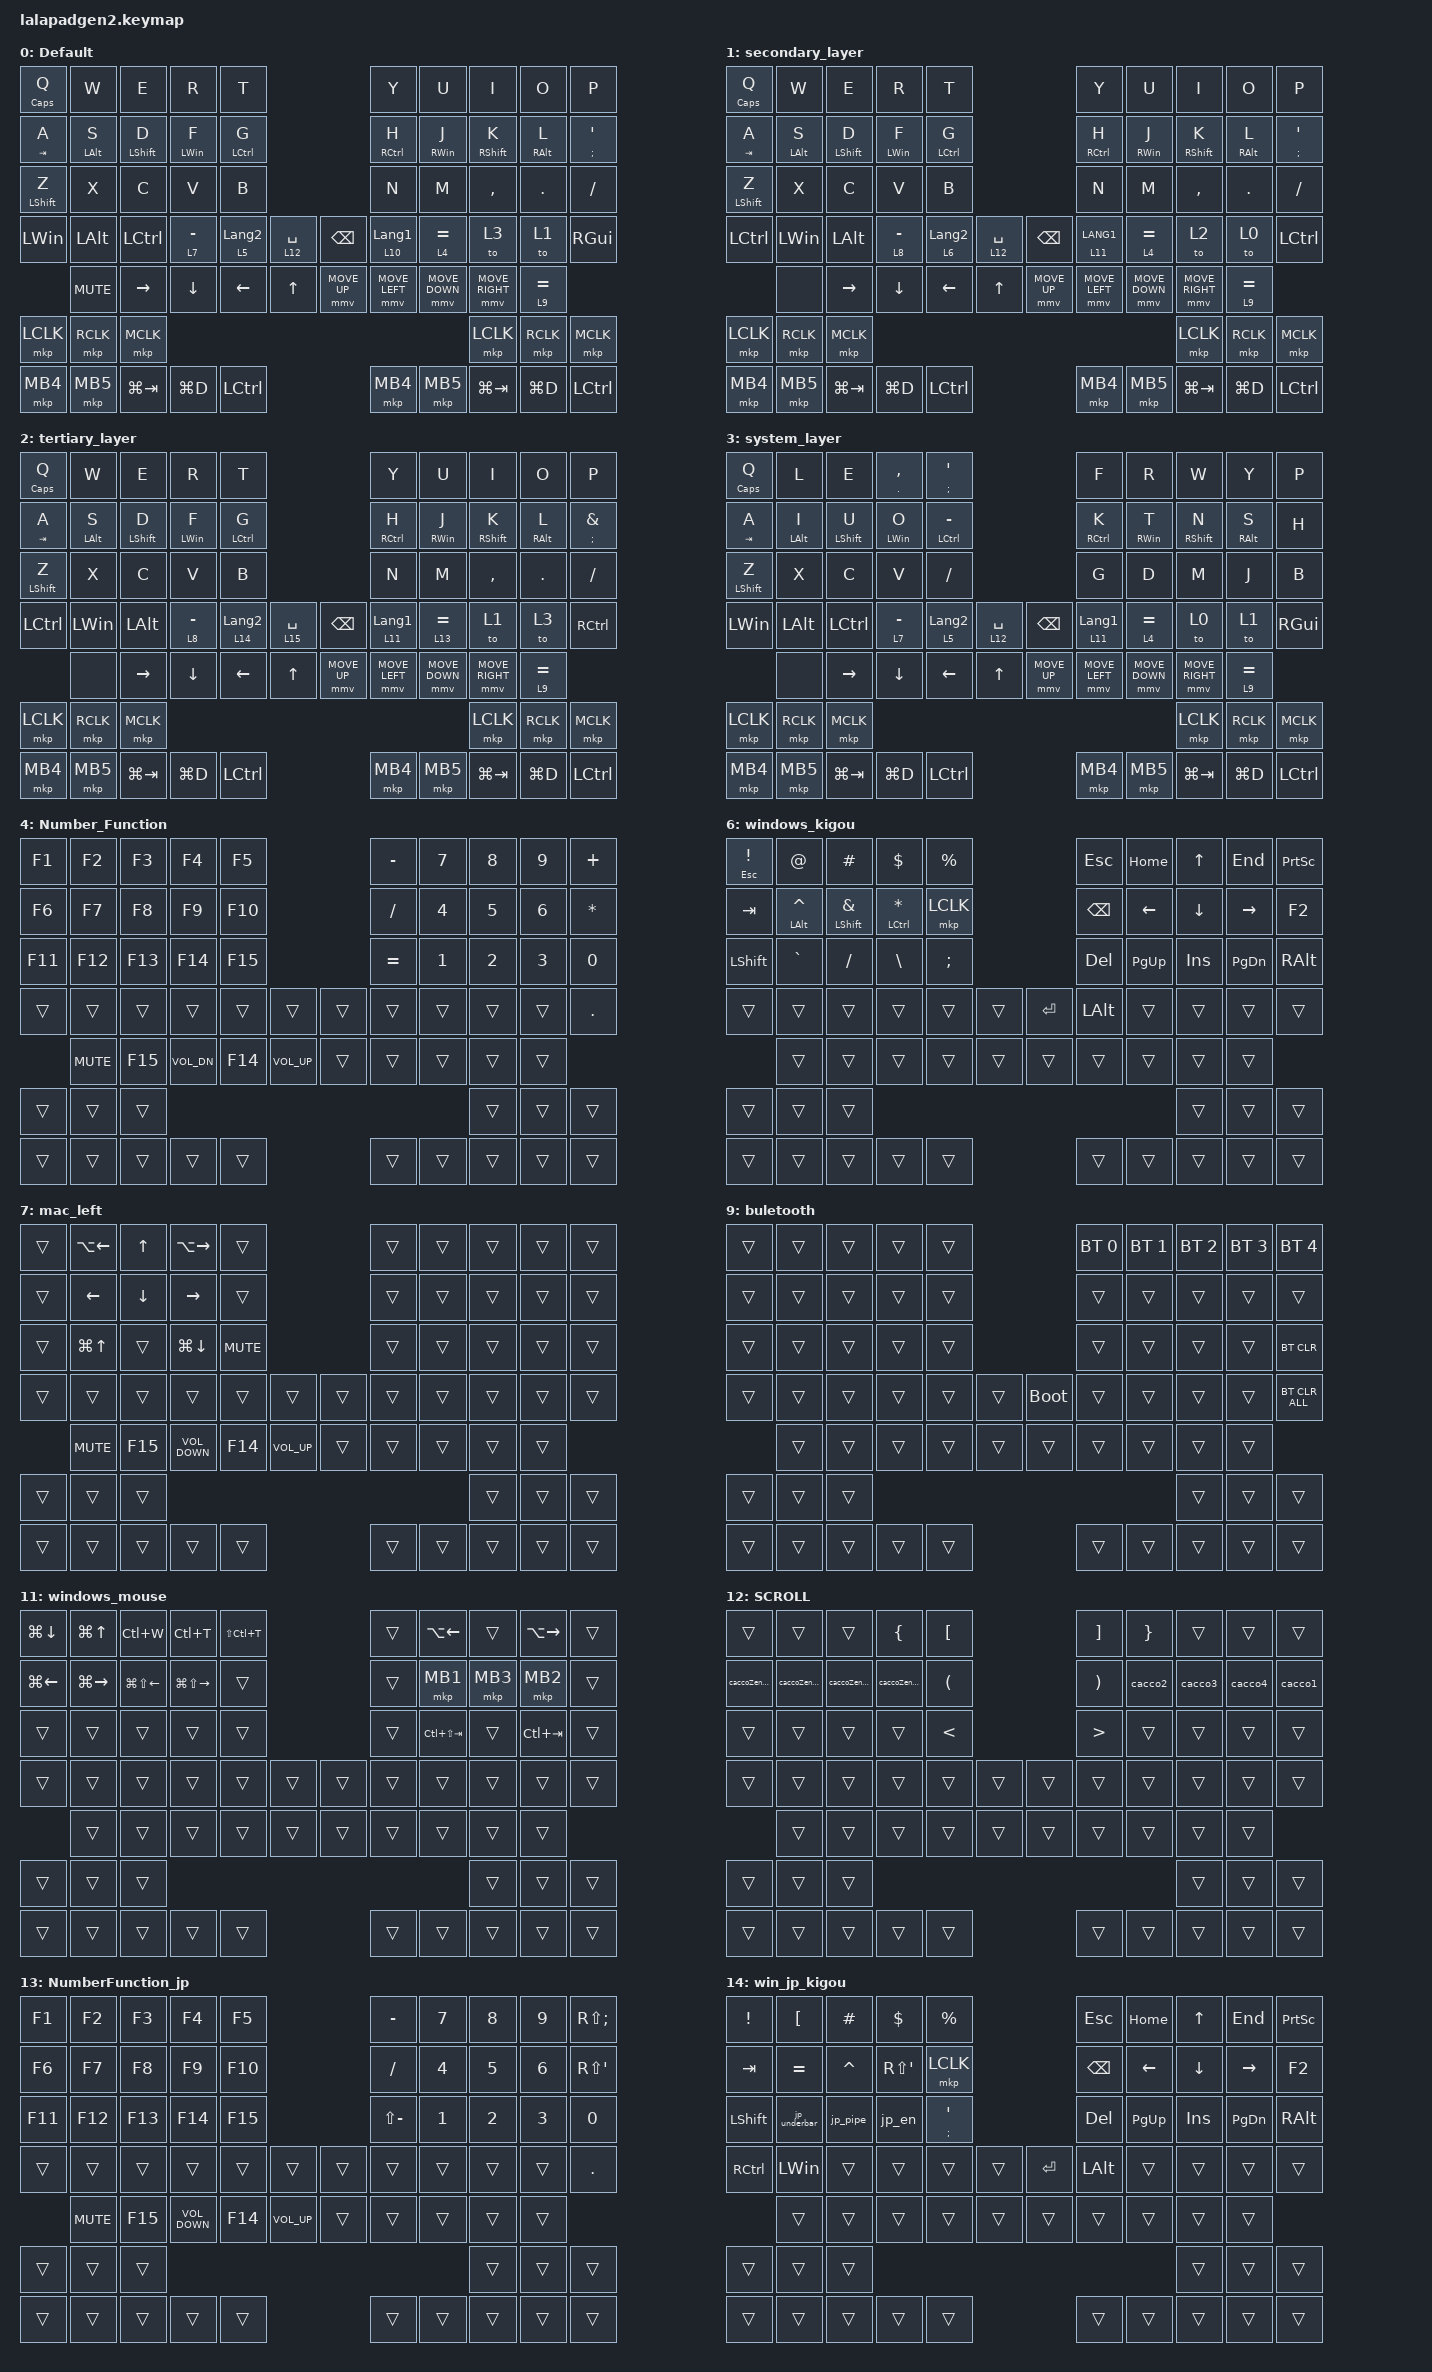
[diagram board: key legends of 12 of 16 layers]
#include <input/processors.dtsi>
#include <dt-bindings/zmk/zip_dynamic_scale.h>
#include <behaviors.dtsi>
#include <dt-bindings/zmk/bt.h>
#include <dt-bindings/zmk/keys.h>
#include <dt-bindings/zmk/pointing.h>

#define DEFAULT_LAYER   0
#define SECONDARY_LAYER 1
#define TERTIARY_LAYER  2
#define SYSTEM_LAYER    3

// &mt { quick-tap-ms = <200>; };

&mt {
    quick-tap-ms = <0>;
    flavor = "balanced";
};

// &lt { quick-tap-ms = <200>; };

&lt {
    quick-tap-ms = <300>;
    flavor = "balanced";
};

/ {
    behaviors {
        zip_dyn_scale: zip_dyn_scale {
            compatible = "zmk,behavior-zip-dynamic-scale";
            #binding-cells = <2>;
        };

        zip_dyn_scale_set: zip_dyn_scale_set {
            compatible = "zmk,behavior-zip-dynamic-scale-set";
            #binding-cells = <2>;
        };

        mt2: mod_tap2 {
            compatible = "zmk,behavior-hold-tap";
            #binding-cells = <2>;
            flavor = "tap-preferred";
            tapping-term-ms = <200>;
            quick-tap-ms = <200>;
            require-prior-idle-ms = <125>;
            bindings = <&kp>, <&kp>;
        };

        tap_dance_layer_1and2: tap_dance_layer_1and2 {
            compatible = "zmk,behavior-tap-dance";
            label = "td_mo12";
            #binding-cells = <0>;
            bindings = <&mo 1>, <&mo 2>;
        };
    };

    combos {
        compatible = "zmk,combos";

        CONBO_ESC {
            bindings = <&kp ESCAPE>;
            key-positions = <0 1>;
            layers = <12>;
        };

        COMBO_TAB {
            bindings = <&kp TAB>;
            key-positions = <10 11>;
            layers = <12>;
        };
    };

    macros {
        to_layer_0: to_layer_0 {
            compatible = "zmk,behavior-macro-one-param";
            #binding-cells = <1>;
            bindings = <&to 1 &macro_param_1to1 &kp MACRO_PLACEHOLDER>;
            label = "TO_LAYER_0";
        };

        cacco1: cacco1 {
            compatible = "zmk,behavior-macro";
            #binding-cells = <0>;
            bindings = <&kp LANGUAGE_1 &kp LEFT_BRACE &kp RIGHT_BRACE &kp RET &kp LEFT_ARROW>;
            label = "CACCO1";
        };

        cacco2: cacco2 {
            compatible = "zmk,behavior-macro";
            #binding-cells = <0>;
            bindings = <&kp LANGUAGE_1 &kp LEFT_PARENTHESIS &kp RIGHT_PARENTHESIS &kp RETURN &kp LEFT>;
            label = "CACCO2";
        };

        cacco3: cacco3 {
            compatible = "zmk,behavior-macro";
            #binding-cells = <0>;
            bindings = <&kp LANGUAGE_1 &kp LEFT_BRACKET &kp RIGHT_BRACKET &kp RET &kp LEFT>;
            label = "CACCO3";
        };

        cacco4: cacco4 {
            compatible = "zmk,behavior-macro";
            #binding-cells = <0>;
            bindings = <&kp LANGUAGE_1 &kp LESS_THAN &kp GREATER_THAN &kp RET &kp LEFT_ARROW>;
            label = "CACCO4";
        };

        caccoZenkaku1: caccoZenkaku1 {
            compatible = "zmk,behavior-macro";
            #binding-cells = <0>;
            bindings = <&kp LANGUAGE_2 &kp LEFT_BRACE &kp RIGHT_BRACE &kp LEFT>;
            label = "CACCOZENKAKU1";
        };

        caccoZenkaku2: caccoZenkaku2 {
            compatible = "zmk,behavior-macro";
            #binding-cells = <0>;
            bindings = <&kp LANGUAGE_2 &kp LEFT_PARENTHESIS &kp RIGHT_PARENTHESIS &kp LEFT_ARROW>;
            label = "CACCOZENKAKU2";
        };

        caccoZenkaku3: caccoZenkaku3 {
            compatible = "zmk,behavior-macro";
            #binding-cells = <0>;
            bindings = <&kp LANGUAGE_2 &kp LEFT_BRACKET &kp RIGHT_BRACKET &kp LEFT>;
            label = "CACCOZENKAKU3";
        };

        caccoZenkaku4: caccoZenkaku4 {
            compatible = "zmk,behavior-macro";
            #binding-cells = <0>;
            bindings = <&kp LANGUAGE_2 &kp LESS_THAN &kp GREATER_THAN &kp LEFT>;
            label = "CACCOZENKAKU4";
        };

        cacco1JpHankaku: cacco1JpHankaku {
            compatible = "zmk,behavior-macro";
            #binding-cells = <0>;
            bindings = <&kp LANGUAGE_2 &kp RIGHT_BRACE &kp LS(BACKSLASH) &kp LEFT_ARROW>;
            label = "CACCO1JPHANKAKU";
        };

        cacco2JpHankaku: cacco2JpHankaku {
            compatible = "zmk,behavior-macro";
            #binding-cells = <0>;
            bindings = <&kp LANGUAGE_2 &kp ASTERISK &kp LEFT_PARENTHESIS &kp LEFT>;
            label = "CACCO2JPHANKAKU";
        };

        cacco3JpHankaku: cacco3JpHankaku {
            compatible = "zmk,behavior-macro";
            #binding-cells = <0>;
            bindings = <&kp LANGUAGE_2 &kp RIGHT_BRACKET &kp BACKSLASH &kp LEFT>;
            label = "CACCO3JPHANKAKU";
        };

        cacco4JpHankaku: cacco4JpHankaku {
            compatible = "zmk,behavior-macro";
            #binding-cells = <0>;
            bindings = <&kp LANGUAGE_2 &kp LESS_THAN &kp GREATER_THAN &kp LEFT>;
            label = "CACCO4JPHANKAKU";
        };

        cacco1JpZenkaku: cacco1JpZenkaku {
            compatible = "zmk,behavior-macro";
            #binding-cells = <0>;
            bindings = <&kp LANGUAGE_1 &kp RIGHT_BRACE &kp LS(BACKSLASH) &kp ENTER &kp LEFT>;
            label = "CACCO1JPZENKAKU";
        };

        cacco2JpZenkaku: cacco2JpZenkaku {
            compatible = "zmk,behavior-macro";
            #binding-cells = <0>;
            bindings = <&kp LANGUAGE_1 &kp ASTERISK &kp LEFT_PARENTHESIS &kp ENTER &kp LEFT_ARROW>;
            label = "CACCO2JPZENKAKU";
        };

        cacco3JpZenkaku: cacco3JpZenkaku {
            compatible = "zmk,behavior-macro";
            #binding-cells = <0>;
            bindings = <&kp LANGUAGE_1 &kp RIGHT_BRACKET &kp BACKSLASH &kp ENTER &kp LEFT>;
            label = "CACCO3JPZENKAKU";
        };

        cacco4JpZenkaku: cacco4JpZenkaku {
            compatible = "zmk,behavior-macro";
            #binding-cells = <0>;
            bindings = <&kp LANGUAGE_1 &kp LESS_THAN &kp GREATER_THAN &kp ENTER &kp LEFT>;
            label = "CACCO4JPZENKAKU";
        };

        jp_underbar: jp_underbar {
            compatible = "zmk,behavior-macro";
            #binding-cells = <0>;
            bindings =
                <&kp LANGUAGE_1 &kp L &kp A &kp I>,
                <&macro_wait_time 1>,
                <&kp TAB>,
                <&macro_wait_time 1>,
                <&kp ENTER &kp LANGUAGE_2>;

            label = "JP_UNDERBAR";
            wait-ms = <5>;
        };

        jp_pipe: jp_pipe {
            compatible = "zmk,behavior-macro";
            #binding-cells = <0>;
            bindings =
                <&kp LANGUAGE_1 &kp L &kp U &kp A>,
                <&macro_wait_time 1>,
                <&kp TAB>,
                <&macro_wait_time 1>,
                <&kp ENTER &kp LANGUAGE_2>;

            label = "JP_PIPE";
            wait-ms = <5>;
        };

        jp_en: jp_en {
            compatible = "zmk,behavior-macro";
            #binding-cells = <0>;
            bindings =
                <&kp LANG_HANGEUL &kp L &kp E &kp A>,
                <&macro_wait_time 1>,
                <&kp TAB>,
                <&macro_wait_time 1>,
                <&kp ENTER &kp LANGUAGE_2>;

            label = "JP_EN";
            wait-ms = <5>;
        };
    };

    keymap {
        compatible = "zmk,keymap";

        mac_default {
            display-name = "Default";
            bindings = <
&mt CAPS Q         &kp W           &kp E         &kp R           &kp T                                          &kp Y              &kp U            &kp I            &kp O            &kp P
&mt TAB A          &mt LEFT_ALT S  &mt LSHIFT D  &mt LEFT_WIN F  &mt LCTRL G                                    &mt RCTRL H        &mt RIGHT_WIN J  &mt RSHIFT K     &mt RIGHT_ALT L  &mt SEMICOLON SINGLE_QUOTE
&mt2 LEFT_SHIFT Z  &kp X           &kp C         &kp V           &kp B                                          &kp N              &kp M            &kp COMMA        &kp PERIOD       &kp SLASH
&kp LEFT_WIN       &kp LEFT_ALT    &kp LCTRL     &lt 7 MINUS     &lt 5 LANGUAGE_2  &lt 12 SPACE  &kp BACKSPACE  &lt 10 LANGUAGE_1  &lt 4 EQUAL      &to 3            &to 1            &kp RIGHT_GUI
                   &kp C_MUTE      &kp RIGHT     &kp DOWN        &kp LEFT          &kp UP        &mmv MOVE_UP   &mmv MOVE_LEFT     &mmv MOVE_DOWN   &mmv MOVE_RIGHT  &lt 9 EQUAL
&mkp LCLK          &mkp RCLK       &mkp MCLK                                                                                                        &mkp LCLK        &mkp RCLK        &mkp MCLK
&mkp MB4           &mkp MB5        &kp LG(TAB)   &kp LG(D)       &kp LCTRL                                      &mkp MB4           &mkp MB5         &kp LG(TAB)      &kp LG(D)        &kp LCTRL
            >;
        };

        windows_default {
            display-name = "secondary_layer";
            bindings = <
&mt CAPS Q         &kp W           &kp E         &kp R           &kp T                                          &kp Y           &kp U            &kp I            &kp O            &kp P
&mt TAB A          &mt LEFT_ALT S  &mt LSHIFT D  &mt LEFT_WIN F  &mt LCTRL G                                    &mt RCTRL H     &mt RIGHT_WIN J  &mt RSHIFT K     &mt RIGHT_ALT L  &mt SEMICOLON SINGLE_QUOTE
&mt2 LEFT_SHIFT Z  &kp X           &kp C         &kp V           &kp B                                          &kp N           &kp M            &kp COMMA        &kp PERIOD       &kp SLASH
&kp LCTRL          &kp LEFT_WIN    &kp LEFT_ALT  &lt 8 MINUS     &lt 6 LANGUAGE_2  &lt 12 SPACE  &kp BACKSPACE  &lt 11 LANG1    &lt 4 EQUAL      &to 2            &to 0            &kp LCTRL
                   &none           &kp RIGHT     &kp DOWN        &kp LEFT          &kp UP        &mmv MOVE_UP   &mmv MOVE_LEFT  &mmv MOVE_DOWN   &mmv MOVE_RIGHT  &lt 9 EQUAL
&mkp LCLK          &mkp RCLK       &mkp MCLK                                                                                                     &mkp LCLK        &mkp RCLK        &mkp MCLK
&mkp MB4           &mkp MB5        &kp LG(TAB)   &kp LG(D)       &kp LCTRL                                      &mkp MB4        &mkp MB5         &kp LG(TAB)      &kp LG(D)        &kp LCTRL
            >;
        };

        windows_jp {
            display-name = "tertiary_layer";
            bindings = <
&mt CAPS Q         &kp W           &kp E         &kp R           &kp T                                           &kp Y              &kp U            &kp I            &kp O            &kp P
&mt TAB A          &mt LEFT_ALT S  &mt LSHIFT D  &mt LEFT_WIN F  &mt LCTRL G                                     &mt RCTRL H        &mt RIGHT_WIN J  &mt RSHIFT K     &mt RIGHT_ALT L  &mt SEMICOLON AMPERSAND
&mt2 LEFT_SHIFT Z  &kp X           &kp C         &kp V           &kp B                                           &kp N              &kp M            &kp COMMA        &kp PERIOD       &kp SLASH
&kp LCTRL          &kp LEFT_WIN    &kp LEFT_ALT  &lt 8 MINUS     &lt 14 LANGUAGE_2  &lt 15 SPACE  &kp BACKSPACE  &lt 11 LANGUAGE_1  &lt 13 EQUAL     &to 1            &to 3            &kp RCTRL
                   &none           &kp RIGHT     &kp DOWN        &kp LEFT           &kp UP        &mmv MOVE_UP   &mmv MOVE_LEFT     &mmv MOVE_DOWN   &mmv MOVE_RIGHT  &lt 9 EQUAL
&mkp LCLK          &mkp RCLK       &mkp MCLK                                                                                                         &mkp LCLK        &mkp RCLK        &mkp MCLK
&mkp MB4           &mkp MB5        &kp LG(TAB)   &kp LG(D)       &kp LCTRL                                       &mkp MB4           &mkp MB5         &kp LG(TAB)      &kp LG(D)        &kp LCTRL
            >;
        };

        mac_onisi {
            display-name = "system_layer";
            bindings = <
&mt CAPS Q         &kp L           &kp E         &mt PERIOD COMMA  &mt SEMICOLON SQT                               &kp F              &kp R            &kp W            &kp Y            &kp P
&mt TAB A          &mt LEFT_ALT I  &mt LSHIFT U  &mt LEFT_WIN O    &mt LCTRL MINUS                                 &mt RCTRL K        &mt RIGHT_WIN T  &mt RSHIFT N     &mt RIGHT_ALT S  &kp H
&mt2 LEFT_SHIFT Z  &kp X           &kp C         &kp V             &kp SLASH                                       &kp G              &kp D            &kp M            &kp J            &kp B
&kp LEFT_WIN       &kp LEFT_ALT    &kp LCTRL     &lt 7 MINUS       &lt 5 LANGUAGE_2   &lt 12 SPACE  &kp BACKSPACE  &lt 11 LANGUAGE_1  &lt 4 EQUAL      &to 0            &to 1            &kp RIGHT_GUI
                   &none           &kp RIGHT     &kp DOWN          &kp LEFT           &kp UP        &mmv MOVE_UP   &mmv MOVE_LEFT     &mmv MOVE_DOWN   &mmv MOVE_RIGHT  &lt 9 EQUAL
&mkp LCLK          &mkp RCLK       &mkp MCLK                                                                                                           &mkp LCLK        &mkp RCLK        &mkp MCLK
&mkp MB4           &mkp MB5        &kp LG(TAB)   &kp LG(D)         &kp LCTRL                                       &mkp MB4           &mkp MB5         &kp LG(TAB)      &kp LG(D)        &kp LCTRL
            >;
        };

        Number_Function {
            bindings = <
&kp F1   &kp F2      &kp F3   &kp F4        &kp F5                            &kp MINUS  &kp N7  &kp N8  &kp N9  &kp PLUS
&kp F6   &kp F7      &kp F8   &kp F9        &kp F10                           &kp SLASH  &kp N4  &kp N5  &kp N6  &kp ASTERISK
&kp F11  &kp F12     &kp F13  &kp F14       &kp F15                           &kp EQUAL  &kp N1  &kp N2  &kp N3  &kp N0
&trans   &trans      &trans   &trans        &trans   &trans           &trans  &trans     &trans  &trans  &trans  &kp DOT
         &kp C_MUTE  &kp F15  &kp C_VOL_DN  &kp F14  &kp C_VOLUME_UP  &trans  &trans     &trans  &trans  &trans
&trans   &trans      &trans                                                                      &trans  &trans  &trans
&trans   &trans      &trans   &trans        &trans                            &trans     &trans  &trans  &trans  &trans
            >;
        };

        mac_kigou {
            bindings = <
&mt ESCAPE EXCLAMATION  &kp AT_SIGN         &kp HASH                  &kp DOLLAR          &kp PERCENT                       &kp ESCAPE     &kp LG(LEFT)      &kp UP_ARROW  &kp LG(RIGHT)  &kp LC(LS(LG(NUMBER_4)))
&kp TAB                 &mt LEFT_ALT CARET  &mt LEFT_SHIFT AMPERSAND  &mt LCTRL ASTERISK  &mkp LCLK                         &kp BACKSPACE  &kp LEFT_ARROW    &kp DOWN      &kp RIGHT      &kp LC(U)
&kp LSHIFT              &kp GRAVE           &kp SLASH                 &kp BACKSLASH       &kp SEMICOLON                     &kp DELETE     &kp LG(UP_ARROW)  &kp INS       &kp LG(DOWN)   &kp RIGHT_ALT
&trans                  &trans              &trans                    &trans              &trans         &trans  &kp ENTER  &kp LEFT_ALT   &trans            &trans        &trans         &kp LS(LG(NUMBER_3))
                        &kp C_MUTE          &trans                    &trans              &trans         &trans  &trans     &trans         &trans            &trans        &trans
&trans                  &trans              &trans                                                                                                           &trans        &trans         &trans
&trans                  &trans              &trans                    &trans              &trans                            &trans         &trans            &trans        &trans         &trans
            >;
        };

        windows_kigou {
            bindings = <
&mt ESCAPE EXCLAMATION  &kp AT_SIGN         &kp HASH                  &kp DOLLAR          &kp PERCENT                       &kp ESCAPE     &kp HOME        &kp UP_ARROW  &kp END        &kp PRINTSCREEN
&kp TAB                 &mt LEFT_ALT CARET  &mt LEFT_SHIFT AMPERSAND  &mt LCTRL ASTERISK  &mkp LCLK                         &kp BACKSPACE  &kp LEFT_ARROW  &kp DOWN      &kp RIGHT      &kp F2
&kp LSHIFT              &kp GRAVE           &kp SLASH                 &kp BACKSLASH       &kp SEMICOLON                     &kp DELETE     &kp PAGE_UP     &kp INS       &kp PAGE_DOWN  &kp RIGHT_ALT
&trans                  &trans              &trans                    &trans              &trans         &trans  &kp ENTER  &kp LEFT_ALT   &trans          &trans        &trans         &trans
                        &trans              &trans                    &trans              &trans         &trans  &trans     &trans         &trans          &trans        &trans
&trans                  &trans              &trans                                                                                                         &trans        &trans         &trans
&trans                  &trans              &trans                    &trans              &trans                            &trans         &trans          &trans        &trans         &trans
            >;
        };

        mac_left {
            bindings = <
&trans  &kp LA(LEFT_ARROW)  &kp UP_ARROW  &kp LA(RIGHT)      &trans                               &trans  &trans  &trans  &trans  &trans
&trans  &kp LEFT_ARROW      &kp DOWN      &kp RIGHT          &trans                               &trans  &trans  &trans  &trans  &trans
&trans  &kp LG(UP_ARROW)    &trans        &kp LG(DOWN)       &kp C_MUTE                           &trans  &trans  &trans  &trans  &trans
&trans  &trans              &trans        &trans             &trans      &trans           &trans  &trans  &trans  &trans  &trans  &trans
        &kp C_MUTE          &kp F15       &kp C_VOLUME_DOWN  &kp F14     &kp C_VOLUME_UP  &trans  &trans  &trans  &trans  &trans
&trans  &trans              &trans                                                                                &trans  &trans  &trans
&trans  &trans              &trans        &trans             &trans                               &trans  &trans  &trans  &trans  &trans
            >;
        };

        win_left {
            bindings = <
&kp ESCAPE      &kp LC(LS(TAB))   &kp UP_ARROW    &kp LC(TAB)        &trans                   &trans  &trans  &trans  &trans  &trans
&kp HOME        &kp LEFT_ARROW    &kp DOWN_ARROW  &kp RIGHT_ARROW    &kp END                  &trans  &trans  &trans  &trans  &trans
&kp LEFT_SHIFT  &kp LG(LS(LEFT))  &trans          &kp LG(LS(RIGHT))  &trans                   &trans  &trans  &trans  &trans  &trans
&trans          &trans            &trans          &trans             &trans   &trans  &trans  &trans  &trans  &trans  &trans  &trans
                &trans            &trans          &trans             &trans   &trans  &trans  &trans  &trans  &trans  &trans
&trans          &trans            &trans                                                                      &trans  &trans  &trans
&trans          &trans            &trans          &trans             &trans                   &trans  &trans  &trans  &trans
            >;
        };

        buletooth {
            bindings = <
&trans  &trans  &trans  &trans  &trans                       &bt BT_SEL 0  &bt BT_SEL 1  &bt BT_SEL 2  &bt BT_SEL 3  &bt BT_SEL 4
&trans  &trans  &trans  &trans  &trans                       &trans        &trans        &trans        &trans        &trans
&trans  &trans  &trans  &trans  &trans                       &trans        &trans        &trans        &trans        &bt BT_CLR
&trans  &trans  &trans  &trans  &trans  &trans  &bootloader  &trans        &trans        &trans        &trans        &bt BT_CLR_ALL
        &trans  &trans  &trans  &trans  &trans  &trans       &trans        &trans        &trans        &trans
&trans  &trans  &trans                                                                   &trans        &trans        &trans
&trans  &trans  &trans  &trans  &trans                       &trans        &trans        &trans        &trans        &trans
            >;
        };

        mac_mouse {
            bindings = <
&kp LG(LC(LA(N)))  &kp LG(LA(LC(LEFT_ARROW)))  &kp LG(LC(UP_ARROW))    &kp LG(LA(LC(UP_ARROW)))  &kp LG(BACKSLASH)                  &trans  &kp LG(LEFT_BRACKET)  &trans     &kp LG(RIGHT_BRACKET)  &trans
&kp LC(UP)         &kp LG(LC(LEFT))            &kp LG(LC(DOWN_ARROW))  &kp LG(LC(RIGHT))         &kp LG(LS(LC(D)))                  &trans  &mkp LCLK             &mkp MCLK  &mkp RCLK              &trans
&kp LC(DOWN)       &kp LG(LC(LA(DOWN_ARROW)))  &trans                  &kp LC(LA(LG(RIGHT)))     &trans                             &trans  &kp LC(LS(TAB))       &trans     &kp LC(TAB)            &trans
&trans             &trans                      &trans                  &trans                    &trans             &trans  &trans  &trans  &trans                &trans     &trans                 &trans
                   &trans                      &trans                  &trans                    &trans             &trans  &trans  &trans  &trans                &trans     &trans
&trans             &trans                      &trans                                                                                                             &trans     &trans                 &trans
&trans             &trans                      &trans                  &trans                    &trans                             &trans  &trans                &trans     &trans                 &trans
            >;
        };

        windows_mouse {
            bindings = <
&kp LG(DOWN)  &kp LG(UP_ARROW)  &kp LC(W)         &kp LC(T)          &kp LS(LC(T))                  &trans  &kp LA(LEFT)     &trans    &kp LA(RIGHT)  &trans
&kp LG(LEFT)  &kp LG(RIGHT)     &kp LG(LS(LEFT))  &kp LG(LS(RIGHT))  &trans                         &trans  &mkp MB1         &mkp MB3  &mkp MB2       &trans
&trans        &trans            &trans            &trans             &trans                         &trans  &kp LC(LS(TAB))  &trans    &kp LC(TAB)    &trans
&trans        &trans            &trans            &trans             &trans         &trans  &trans  &trans  &trans           &trans    &trans         &trans
              &trans            &trans            &trans             &trans         &trans  &trans  &trans  &trans           &trans    &trans
&trans        &trans            &trans                                                                                       &trans    &trans         &trans
&trans        &trans            &trans            &trans             &trans                         &trans  &trans           &trans    &trans         &trans
            >;
        };

        SCROLL {
            bindings = <
&trans          &trans          &trans          &kp LEFT_BRACE  &kp LEFT_BRACKET                      &kp RIGHT_BRACKET      &kp RIGHT_BRACE  &trans   &trans   &trans
&caccoZenkaku1  &caccoZenkaku4  &caccoZenkaku3  &caccoZenkaku2  &kp LEFT_PARENTHESIS                  &kp RIGHT_PARENTHESIS  &cacco2          &cacco3  &cacco4  &cacco1
&trans          &trans          &trans          &trans          &kp LESS_THAN                         &kp GREATER_THAN       &trans           &trans   &trans   &trans
&trans          &trans          &trans          &trans          &trans                &trans  &trans  &trans                 &trans           &trans   &trans   &trans
                &trans          &trans          &trans          &trans                &trans  &trans  &trans                 &trans           &trans   &trans
&trans          &trans          &trans                                                                                                        &trans   &trans   &trans
&trans          &trans          &trans          &trans          &trans                                &trans                 &trans           &trans   &trans   &trans
            >;
        };

        NumberFunction_jp {
            bindings = <
&kp F1   &kp F2      &kp F3   &kp F4             &kp F5                            &kp MINUS      &kp N7        &kp N8        &kp N9        &kp RS(SEMICOLON)
&kp F6   &kp F7      &kp F8   &kp F9             &kp F10                           &kp SLASH      &kp NUMBER_4  &kp N5        &kp NUMBER_6  &kp RS(SINGLE_QUOTE)
&kp F11  &kp F12     &kp F13  &kp F14            &kp F15                           &kp LS(MINUS)  &kp NUMBER_1  &kp NUMBER_2  &kp NUMBER_3  &kp N0
&trans   &trans      &trans   &trans             &trans   &trans           &trans  &trans         &trans        &trans        &trans        &kp PERIOD
         &kp C_MUTE  &kp F15  &kp C_VOLUME_DOWN  &kp F14  &kp C_VOLUME_UP  &trans  &trans         &trans        &trans        &trans
&trans   &trans      &trans                                                                                     &trans        &trans        &trans
&trans   &trans      &trans   &trans             &trans                            &trans         &trans        &trans        &trans        &trans
            >;
        };

        win_jp_kigou {
            bindings = <
&kp EXCLAMATION  &kp LEFT_BRACKET  &kp HASH   &kp DOLLAR            &kp PERCENT                                    &kp ESC        &kp HOME     &kp UP_ARROW    &kp END        &kp PRINTSCREEN
&kp TAB          &kp EQUAL         &kp CARET  &kp RS(SINGLE_QUOTE)  &mkp LCLK                                      &kp BACKSPACE  &kp LEFT     &kp DOWN_ARROW  &kp RIGHT      &kp F2
&kp LSHIFT       &jp_underbar      &jp_pipe   &jp_en                &mt SEMICOLON SINGLE_QUOTE                     &kp DELETE     &kp PAGE_UP  &kp INS         &kp PAGE_DOWN  &kp RIGHT_ALT
&kp RCTRL        &kp LEFT_WIN      &trans     &trans                &trans                      &trans  &kp ENTER  &kp LEFT_ALT   &trans       &trans          &trans         &trans
                 &trans            &trans     &trans                &trans                      &trans  &trans     &trans         &trans       &trans          &trans
&trans           &trans            &trans                                                                                                      &trans          &trans         &trans
&trans           &trans            &trans     &trans                &trans                                         &trans         &trans       &trans          &trans         &trans
            >;
        };

        windows_jp_kakko {
            bindings = <
&trans            &trans            &trans            &kp RBRC          &kp RIGHT_BRACKET                  &kp BACKSLASH         &kp LS(BACKSLASH)  &trans            &trans            &trans
&cacco1JpHankaku  &cacco4JpHankaku  &cacco3JpHankaku  &cacco2JpHankaku  &kp ASTERISK                       &kp LEFT_PARENTHESIS  &cacco2JpZenkaku   &cacco3JpZenkaku  &cacco4JpZenkaku  &cacco1JpZenkaku
&trans            &trans            &trans            &trans            &kp LESS_THAN                      &kp GREATER_THAN      &trans             &trans            &trans            &trans
&trans            &trans            &trans            &trans            &trans             &trans  &trans  &trans                &trans             &trans            &trans            &trans
                  &trans            &trans            &trans            &trans             &trans  &trans  &trans                &trans             &trans            &trans
&trans            &trans            &trans                                                                                                          &trans            &trans            &trans
&trans            &trans            &trans            &trans            &trans                             &trans                &trans             &trans            &trans            &trans
            >;
        };
    };

    conditional_layers {
        compatible = "zmk,conditional-layers";

        Cond_Syslayer {
            if-layers = <1 2>;
            then-layer = <3>;
        };
    };
};
